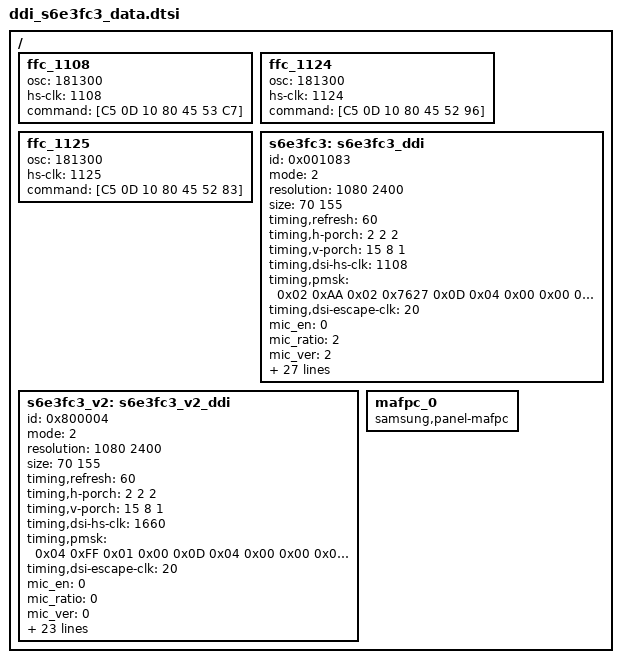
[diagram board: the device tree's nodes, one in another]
/*
 * Samsung Exynos SoC series Panel driver
 *
 * Copyright (c) 2020 Samsung Electronics Co., Ltd
 *
 * This program is free software; you can redistribute it and/or modify
 * it under the terms of the GNU General Public License version 2 as
 * published by the Free Software Foundation.
 */

#include "s5e8825-dsim_freq.dtsi"

/ {
	fragment@panel_drv {
		target-path = "/";
		__overlay__ {
			ffc_1108: ffc_1108 {
				osc = <181300>;
				hs-clk = <1108>;
				command = [C5 0D 10 80 45 53 C7];
			};

			ffc_1124: ffc_1124 {
				osc = <181300>;
				hs-clk = <1124>;
				command = [C5 0D 10 80 45 52 96];
			};

			ffc_1125: ffc_1125 {
				osc = <181300>;
				hs-clk = <1125>;
				command = [C5 0D 10 80 45 52 83];
			};

			s6e3fc3: s6e3fc3_ddi {
				id = <0x001083>;
				mode = <2>;
				resolution = <1080 2400>;
				size = <70 155>;
				timing,refresh = <60>;
				timing,h-porch = <2 2 2>;
				timing,v-porch = <15 8 1>;
				timing,dsi-hs-clk = <1108>;
				timing,pmsk = <
					0x02 0xAA 0x02 0x7627
					0x0D 0x04 0x00 0x00
					0x00 0x00 0x00 0x00
					0x00 0x00>;
				timing,dsi-escape-clk = <20>;
				mic_en = <0>;			/* 0: Disable, 1: Enable */
				mic_ratio = <2>;		/* 0: 1/2 mic, 1: 1/3 mic */
				mic_ver = <2>;			/* 0: mic v1.1, 1: v1.2, 2: v2.0 */
				type_of_ddi = <0>;		/* 0: Samsung Mobile, 1: MAGNA, 2: Normal(Etc) */
				dsc_en = <1>;			/* 0: Disable, 1: Enable */
				dsc_cnt = <1>;			/* used DSC count */
				dsc_slice_num = <2>;		/* count of dsc slice */
				dsc_slice_h = <40>;		/* height of dsc slice */
				data_lane = <4>;		/* number of using data lane */
				cmd_underrun_cnt = <9935>;	/* for underrun detect*/
				mres_en = <1>;
				mres_number = <1>;
				mres_width = <1080>;
				mres_height = <2400>;
				mres_dsc_width = <540>;
				mres_dsc_height = <40>;
				mres_dsc_en = <1>;
				default_mode = <1>;
				/* <xres : yres : fps : lp_ref : dsc_en : slice_w : slice_h> */
				display_mode = <1080 2400 120 2107 1 540 40>,
							 <1080 2400 60 7991 1 540 40>;
				hdr_num = <2>;			/* max: 4 */
				hdr_type = <2 3 0 0>;		/* 1: DOLBY_VISION, 2: HDR10, 3: HLG */
				hdr_max_luma = <4500000>;	/* 450 */
				hdr_max_avg_luma = <1200000>;	/* 120 */
				hdr_min_luma = <5>;		/* 0.0005 */
				color_mode = <0 7 9>;  /* color mode : NATIVE, SRGB, P3 */
				dynamic_mipi_tbl = <&dsim_freq_1108 &dsim_freq_1124 &dsim_freq_1125>;
				dynamic_mipi_ffc0 = <&ffc_1108 &ffc_1124 &ffc_1125>;
			};

			s6e3fc3_v2: s6e3fc3_v2_ddi {
				id = <0x800004>;
				mode = <2>;
				resolution = <1080 2400>;
				size = <70 155>;
				timing,refresh = <60>;
				timing,h-porch = <2 2 2>;
				timing,v-porch = <15 8 1>;
				timing,dsi-hs-clk = <1660>;
				timing,pmsk = <
					0x04 0xFF 0x01 0x00
					0x0D 0x04 0x00 0x00
					0x00 0x00 0x00 0x00
					0x00 0x00>;
				timing,dsi-escape-clk = <20>;
				mic_en = <0>;			/* 0: Disable, 1: Enable */
				mic_ratio = <0>;		/* 0: 1/2 mic, 1: 1/3 mic */
				mic_ver = <0>;			/* 0: mic v1.1, 1: v1.2, 2: v2.0 */
				type_of_ddi = <0>;		/* 0: Samsung Mobile, 1: MAGNA, 2: Normal(Etc) */
				dsc_en = <1>;			/* 0: Disable, 1: Enable */
				dsc_cnt = <1>;			/* used DSC count */
				dsc_slice_num = <2>;		/* count of dsc slice */
				dsc_slice_h = <40>;		/* height of dsc slice */
				data_lane = <4>;		/* number of using data lane */
				cmd_underrun_cnt = <9935>;	/* for underrun detect*/
				mres_en = <1>;
				mres_number = <1>;
				mres_width = <1080>;
				mres_height = <2400>;
				mres_dsc_width = <540>;
				mres_dsc_height = <40>;
				mres_dsc_en = <1>;
				default_mode = <1>;
				/* <xres : yres : fps : lp_ref : dsc_en : slice_w : slice_h> */
				display_mode =  <1080 2400 90 5093 1 540 40>,
							 <1080 2400 60 9935 1 540 40>;

				hdr_num = <2>;			/* max: 4 */
				hdr_type = <2 3 0 0>;		/* 1: DOLBY_VISION, 2: HDR10, 3: HLG */
				hdr_max_luma = <4500000>;	/* 450 */
				hdr_max_avg_luma = <1200000>;	/* 120 */
				hdr_min_luma = <5>;		/* 0.0005 */
				color_mode = <0 7 9>;  /* color mode : NATIVE, SRGB, P3 */
			};

			mafpc_0: mafpc_0 {
				compatible = "samsung,panel-mafpc";
				status = "okay";
			};
		};
	};
};
